# f28e12x_clk_cfg_regs register map
Vendor: Texas Instruments
Peripheral module from a debugger description file (folder C2000).
Address unit: 16 bits
Registers are 32-bit, read-write, no defined reset value unless marked. A register's access mark holds for its fields unless they carry their own. Offsets are as the file gives them; lines under a group give offsets from that group; [hi:lo] are bit positions; {n}, {i} and the like mark numbered series; 'fields as' and 'values as' point back to an identical list; <NAME> marks a mode.

## CLK_CFG_REGS — CLK CFG Registers
0x00 CLKCFGLOCK — Lock bit for CLKCFG registers
  [0] ALL
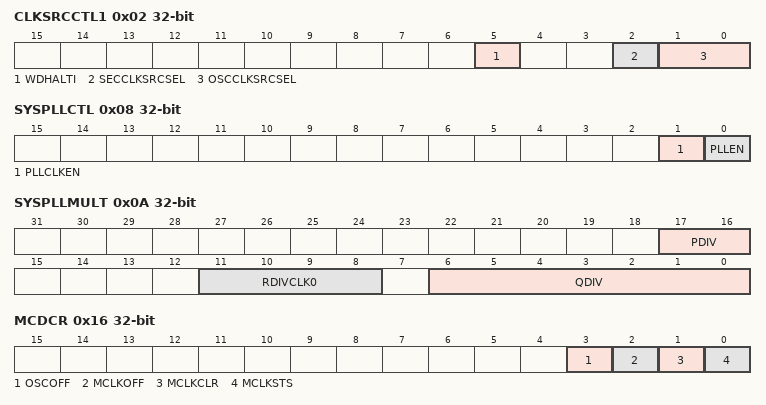
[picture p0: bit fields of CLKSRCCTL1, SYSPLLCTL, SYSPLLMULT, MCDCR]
0x02 CLKSRCCTL1 — Clock Source Control register-1
  [5] WDHALTI — Watchdog HALT Mode Ignore Bit
  [2] SECCLKSRCSEL — SECCLK Source Select Bit
  [1:0] OSCCLKSRCSEL — OSCCLK Source Select Bits
0x04 CLKSRCCTL2 — Clock Source Control register-2
  [1:0] CANABCLKSEL — CANA Bit Clock Source Select Bit
0x06 CLKSRCCTL3 — Clock Source Control register-3
  [3:0] XCLKOUTSEL — XCLKOUT Source Select Bit
0x08 SYSPLLCTL — SYSPLL Control register
  [1] PLLCLKEN — SYSPLL bypassed or included in the PLLSYSCLK path
  [0] PLLEN — SYSPLL enable/disable bit
0x0A SYSPLLMULT — SYSPLL Multiplier register
  [17:16] PDIV — Reference Clock Divider
  [11:8] RDIVCLK0 — Output Clock Divider
  [6:0] QDIV — SYSPLL Feedback Divider (decides the Multiplier factor)
0x0C SYSPLLSTS ro — SYSPLL Status register
  [0] LOCKS — SYSPLL Lock Status Bit
0x0E SYSCLKDIVSEL — System Clock Divider Select register
  [5:0] PLLSYSCLKDIV — PLLSYSCLK Divide Select
0x10 PERCLKDIVSEL access not given — Peripheral Clock Divider Select register
0x12 XCLKOUTDIVSEL — XCLKOUT Divider Select register
  [1:0] XCLKOUTDIV — XCLKOUT Divide Select
0x14 LOSPCP — Low Speed Clock Source Prescalar
  [2:0] LSPCLKDIV — LSPCLK Divide Select
0x16 MCDCR access per field — Missing Clock Detect Control Register
  [3] OSCOFF rw — Oscillator Clock Off Bit
  [2] MCLKOFF rw — Missing Clock Detect Off Bit
  [1] MCLKCLR rw — Missing Clock Clear Bit
  [0] MCLKSTS ro — Missing Clock Status Bit
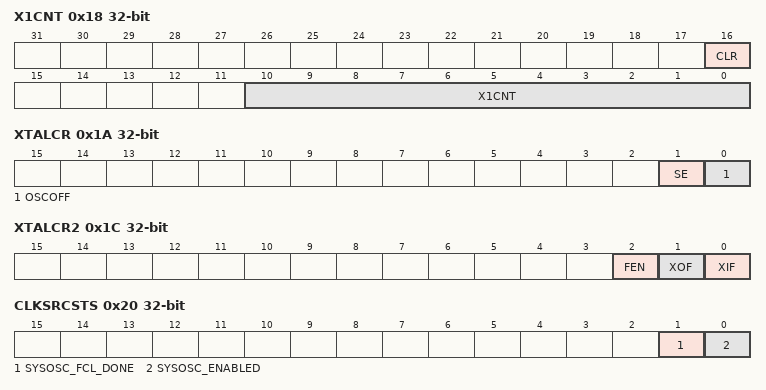
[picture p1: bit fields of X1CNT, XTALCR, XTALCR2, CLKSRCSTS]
0x18 X1CNT access per field — 10-bit Counter on X1 Clock
  [16] CLR rw — X1 Counter Clear
  [10:0] X1CNT ro — X1 Counter
0x1A XTALCR — XTAL Control Register
  [1] SE — XTAL Oscilator in Single-Ended mode
  [0] OSCOFF — XTAL Oscillator powered-down
0x1C XTALCR2 — XTAL Control Register for pad init
  [2] FEN — XOSC pads initialisation enable
  [1] XOF — XO Initial value deposited before XOSC start
  [0] XIF — XI Initial value deposited before XOSC start
0x1E CLKFAILCFG — Clock Fail cause Configuration
  [0] DCC0_ERROR_EN — DCC0 Error causes Clock fail NMI, ERROR
0x20 CLKSRCSTS ro — Clock Source Status
  [1] SYSOSC_FCL_DONE — SYSOSC FCL done status
  [0] SYSOSC_ENABLED — SYSOSC enabled status
